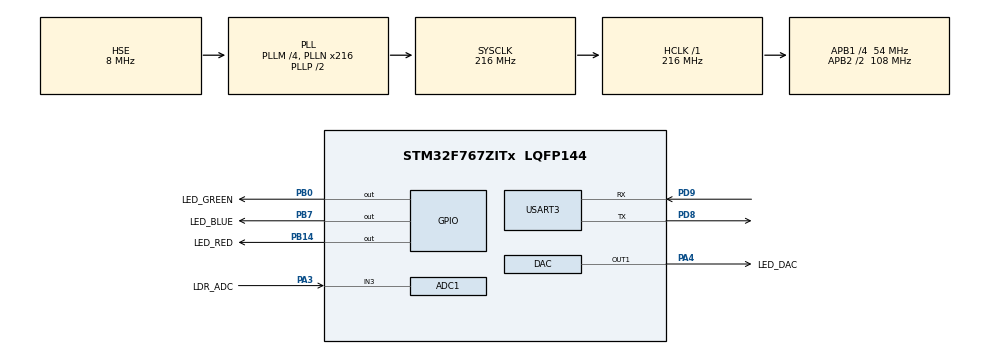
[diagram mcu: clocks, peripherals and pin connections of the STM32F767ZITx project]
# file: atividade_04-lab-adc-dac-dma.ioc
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ADC1.Channel-0\#ChannelRegularConversion=ADC_CHANNEL_3
ADC1.ClockPrescaler=ADC_CLOCK_SYNC_PCLK_DIV8
ADC1.ContinuousConvMode=ENABLE
ADC1.DMAContinuousRequests=ENABLE
ADC1.NbrOfConversionFlag=1
ADC1.Rank-0\#ChannelRegularConversion=1
ADC1.SamplingTime-0\#ChannelRegularConversion=ADC_SAMPLETIME_480CYCLES
ADC1.master=1
Dma.ADC1.0.Direction=DMA_PERIPH_TO_MEMORY
Dma.ADC1.0.FIFOMode=DMA_FIFOMODE_DISABLE
Dma.ADC1.0.Instance=DMA2_Stream0
Dma.ADC1.0.MemDataAlignment=DMA_MDATAALIGN_HALFWORD
Dma.ADC1.0.MemInc=DMA_MINC_ENABLE
Dma.ADC1.0.Mode=DMA_CIRCULAR
Dma.ADC1.0.PeriphDataAlignment=DMA_PDATAALIGN_HALFWORD
Dma.ADC1.0.PeriphInc=DMA_PINC_DISABLE
Dma.ADC1.0.Priority=DMA_PRIORITY_LOW
Dma.Request0=ADC1
Dma.Request1=USART3_RX
Dma.USART3_RX.1.Direction=DMA_PERIPH_TO_MEMORY
Dma.USART3_RX.1.FIFOMode=DMA_FIFOMODE_DISABLE
Dma.USART3_RX.1.Instance=DMA1_Stream1
Dma.USART3_RX.1.MemDataAlignment=DMA_MDATAALIGN_BYTE
Dma.USART3_RX.1.MemInc=DMA_MINC_ENABLE
Dma.USART3_RX.1.Mode=DMA_CIRCULAR
Dma.USART3_RX.1.PeriphDataAlignment=DMA_PDATAALIGN_BYTE
Dma.USART3_RX.1.PeriphInc=DMA_PINC_DISABLE
Dma.USART3_RX.1.Priority=DMA_PRIORITY_MEDIUM
Mcu.Family=STM32F7
Mcu.Name=STM32F767ZITx
Mcu.Package=LQFP144
NVIC.DMA1_Stream1_IRQn=true\:5\:0\:false\:false\:true\:false\:true\:true
NVIC.DMA2_Stream0_IRQn=true\:6\:0\:false\:false\:true\:false\:true\:true
NVIC.PriorityGroup=NVIC_PRIORITYGROUP_4
NVIC.USART3_IRQn=true\:5\:0\:false\:false\:true\:true\:true\:true
PA13.Mode=Serial_Wire
PA13.Signal=SYS_JTMS-SWDIO
PA14.Mode=Serial_Wire
PA14.Signal=SYS_JTCK-SWCLK
PA3.GPIO_Label=LDR_ADC
PA3.Signal=ADCx_IN3
PA4.GPIO_Label=LED_DAC
PA4.Signal=COMP_DAC1_group
PB0.GPIO_Label=LED_GREEN
PB0.Signal=GPIO_Output
PB14.GPIO_Label=LED_RED
PB14.Signal=GPIO_Output
PB7.GPIO_Label=LED_BLUE
PB7.Signal=GPIO_Output
PD8.Mode=Asynchronous
PD8.Signal=USART3_TX
PD9.Mode=Asynchronous
PD9.Signal=USART3_RX
PH0/OSC_IN.Mode=HSE-External-Clock-Source
PH0/OSC_IN.Signal=RCC_OSC_IN
PH1/OSC_OUT.Mode=HSE-External-Clock-Source
PH1/OSC_OUT.Signal=RCC_OSC_OUT
ProjectManager.HeapSize=0x200
ProjectManager.StackSize=0x400
ProjectManager.TargetToolchain=STM32CubeIDE
RCC.AHBFreq_Value=216000000
RCC.APB1CLKDivider=RCC_HCLK_DIV4
RCC.APB1Freq_Value=54000000
RCC.APB1TimFreq_Value=108000000
RCC.APB2CLKDivider=RCC_HCLK_DIV2
RCC.APB2Freq_Value=108000000
RCC.APB2TimFreq_Value=216000000
RCC.CortexFreq_Value=216000000
RCC.HCLKFreq_Value=216000000
RCC.HSE_VALUE=8000000
RCC.HSI_VALUE=16000000
RCC.LSE_VALUE=32768
RCC.PLLM=4
RCC.PLLN=216
RCC.PLLSourceVirtual=RCC_PLLSOURCE_HSE
RCC.SYSCLKFreq_VALUE=216000000
RCC.SYSCLKSource=RCC_SYSCLKSOURCE_PLLCLK
RCC.USBFreq_Value=216000000
RCC.VCOOutputFreq_Value=432000000
SH.ADCx_IN3.0=ADC1_IN3,IN3
SH.COMP_DAC1_group.0=DAC_OUT1,DAC_OUT1
USART3.VirtualMode-Asynchronous=VM_ASYNC
board=custom

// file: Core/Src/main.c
/* USER CODE BEGIN Header */
/**
  ******************************************************************************
  * @file           : main.c
  * @brief          : Main program body
  ******************************************************************************
  * @attention
  *
  * Copyright (c) 2026 STMicroelectronics.
  * All rights reserved.
  *
  * This software is licensed under terms that can be found in the LICENSE file
  * in the root directory of this software component.
  * If no LICENSE file comes with this software, it is provided AS-IS.
  *
  ******************************************************************************
  */
/* USER CODE END Header */
#include "main.h"

/* USER CODE BEGIN Includes */
#include "bsp.h"
#include "app.h"

/* USER CODE END Includes */

ADC_HandleTypeDef hadc1;
DMA_HandleTypeDef hdma_adc1;

DAC_HandleTypeDef hdac;

UART_HandleTypeDef huart3;
DMA_HandleTypeDef hdma_usart3_rx;

void SystemClock_Config(void);
static void MX_GPIO_Init(void);
static void MX_DMA_Init(void);
static void MX_ADC1_Init(void);
static void MX_DAC_Init(void);
static void MX_USART3_UART_Init(void);

int main(void)
{

  /* MCU Configuration--------------------------------------------------------*/

  /* Reset of all peripherals, Initializes the Flash interface and the Systick. */
  HAL_Init();

  /* Configure the system clock */
  SystemClock_Config();

  /* Initialize all configured peripherals */
  MX_GPIO_Init();
  MX_DMA_Init();
  MX_ADC1_Init();
  MX_DAC_Init();
  MX_USART3_UART_Init();
  /* USER CODE BEGIN 2 */
  /* camada de hardware: LEDs, console (DMA), DAC e ADC (DMA) */
  bool bsp_ok = bsp_init(&hadc1, &hdac, &huart3);
  app_init(bsp_ok);           /* digipot + linha de comando */

  /* USER CODE END 2 */

  /* Infinite loop */
  while (1)
  {

    /* USER CODE BEGIN 3 */
    app_loop();               /* superloop bare-metal */
  }
  /* USER CODE END 3 */
}

void SystemClock_Config(void)
{
  RCC_OscInitTypeDef RCC_OscInitStruct = {0};
  RCC_ClkInitTypeDef RCC_ClkInitStruct = {0};

  /** Configure the main internal regulator output voltage
  */
  __HAL_RCC_PWR_CLK_ENABLE();
  __HAL_PWR_VOLTAGESCALING_CONFIG(PWR_REGULATOR_VOLTAGE_SCALE1);

  /** Initializes the RCC Oscillators according to the specified parameters
  * in the RCC_OscInitTypeDef structure.
  */
  RCC_OscInitStruct.OscillatorType = RCC_OSCILLATORTYPE_HSE;
  RCC_OscInitStruct.HSEState = RCC_HSE_BYPASS;
  RCC_OscInitStruct.PLL.PLLState = RCC_PLL_ON;
  RCC_OscInitStruct.PLL.PLLSource = RCC_PLLSOURCE_HSE;
  RCC_OscInitStruct.PLL.PLLM = 4;
  RCC_OscInitStruct.PLL.PLLN = 216;
  RCC_OscInitStruct.PLL.PLLP = RCC_PLLP_DIV2;
  RCC_OscInitStruct.PLL.PLLQ = 2;
  RCC_OscInitStruct.PLL.PLLR = 2;
  if (HAL_RCC_OscConfig(&RCC_OscInitStruct) != HAL_OK)
  {
    Error_Handler();
  }

  /** Activate the Over-Drive mode
  */
  if (HAL_PWREx_EnableOverDrive() != HAL_OK)
  {
    Error_Handler();
  }

  /** Initializes the CPU, AHB and APB buses clocks
  */
  RCC_ClkInitStruct.ClockType = RCC_CLOCKTYPE_HCLK|RCC_CLOCKTYPE_SYSCLK
                              |RCC_CLOCKTYPE_PCLK1|RCC_CLOCKTYPE_PCLK2;
  RCC_ClkInitStruct.SYSCLKSource = RCC_SYSCLKSOURCE_PLLCLK;
  RCC_ClkInitStruct.AHBCLKDivider = RCC_SYSCLK_DIV1;
  RCC_ClkInitStruct.APB1CLKDivider = RCC_HCLK_DIV4;
  RCC_ClkInitStruct.APB2CLKDivider = RCC_HCLK_DIV2;

  if (HAL_RCC_ClockConfig(&RCC_ClkInitStruct, FLASH_LATENCY_7) != HAL_OK)
  {
    Error_Handler();
  }
}

static void MX_ADC1_Init(void)
{

  ADC_ChannelConfTypeDef sConfig = {0};

  /** Configure the global features of the ADC (Clock, Resolution, Data Alignment and number of conversion)
  */
  hadc1.Instance = ADC1;
  hadc1.Init.ClockPrescaler = ADC_CLOCK_SYNC_PCLK_DIV8;
  hadc1.Init.Resolution = ADC_RESOLUTION_12B;
  hadc1.Init.ScanConvMode = ADC_SCAN_DISABLE;
  hadc1.Init.ContinuousConvMode = ENABLE;
  hadc1.Init.DiscontinuousConvMode = DISABLE;
  hadc1.Init.ExternalTrigConvEdge = ADC_EXTERNALTRIGCONVEDGE_NONE;
  hadc1.Init.ExternalTrigConv = ADC_SOFTWARE_START;
  hadc1.Init.DataAlign = ADC_DATAALIGN_RIGHT;
  hadc1.Init.NbrOfConversion = 1;
  hadc1.Init.DMAContinuousRequests = ENABLE;
  hadc1.Init.EOCSelection = ADC_EOC_SINGLE_CONV;
  if (HAL_ADC_Init(&hadc1) != HAL_OK)
  {
    Error_Handler();
  }

  /** Configure for the selected ADC regular channel its corresponding rank in the sequencer and its sample time.
  */
  sConfig.Channel = ADC_CHANNEL_3;
  sConfig.Rank = ADC_REGULAR_RANK_1;
  sConfig.SamplingTime = ADC_SAMPLETIME_480CYCLES;
  if (HAL_ADC_ConfigChannel(&hadc1, &sConfig) != HAL_OK)
  {
    Error_Handler();
  }

}

static void MX_DAC_Init(void)
{

  DAC_ChannelConfTypeDef sConfig = {0};

  /** DAC Initialization
  */
  hdac.Instance = DAC;
  if (HAL_DAC_Init(&hdac) != HAL_OK)
  {
    Error_Handler();
  }

  /** DAC channel OUT1 config
  */
  sConfig.DAC_Trigger = DAC_TRIGGER_NONE;
  sConfig.DAC_OutputBuffer = DAC_OUTPUTBUFFER_ENABLE;
  if (HAL_DAC_ConfigChannel(&hdac, &sConfig, DAC_CHANNEL_1) != HAL_OK)
  {
    Error_Handler();
  }

}

static void MX_USART3_UART_Init(void)
{

  huart3.Instance = USART3;
  huart3.Init.BaudRate = 115200;
  huart3.Init.WordLength = UART_WORDLENGTH_8B;
  huart3.Init.StopBits = UART_STOPBITS_1;
  huart3.Init.Parity = UART_PARITY_NONE;
  huart3.Init.Mode = UART_MODE_TX_RX;
  huart3.Init.HwFlowCtl = UART_HWCONTROL_NONE;
  huart3.Init.OverSampling = UART_OVERSAMPLING_16;
  huart3.Init.OneBitSampling = UART_ONE_BIT_SAMPLE_DISABLE;
  huart3.AdvancedInit.AdvFeatureInit = UART_ADVFEATURE_NO_INIT;
  if (HAL_UART_Init(&huart3) != HAL_OK)
  {
    Error_Handler();
  }

}

static void MX_DMA_Init(void)
{

  /* DMA controller clock enable */
  __HAL_RCC_DMA2_CLK_ENABLE();
  __HAL_RCC_DMA1_CLK_ENABLE();

  /* DMA interrupt init */
  /* DMA1_Stream1_IRQn interrupt configuration */
  HAL_NVIC_SetPriority(DMA1_Stream1_IRQn, 5, 0);
  HAL_NVIC_EnableIRQ(DMA1_Stream1_IRQn);
  /* DMA2_Stream0_IRQn interrupt configuration */
  HAL_NVIC_SetPriority(DMA2_Stream0_IRQn, 6, 0);
  HAL_NVIC_EnableIRQ(DMA2_Stream0_IRQn);

}

static void MX_GPIO_Init(void)
{
  GPIO_InitTypeDef GPIO_InitStruct = {0};

  /* GPIO Ports Clock Enable */
  __HAL_RCC_GPIOH_CLK_ENABLE();
  __HAL_RCC_GPIOA_CLK_ENABLE();
  __HAL_RCC_GPIOB_CLK_ENABLE();
  __HAL_RCC_GPIOD_CLK_ENABLE();

  /*Configure GPIO pin Output Level */
  HAL_GPIO_WritePin(GPIOB, LED_GREEN_Pin|LED_RED_Pin|LED_BLUE_Pin, GPIO_PIN_RESET);

  /*Configure GPIO pins : LED_GREEN_Pin LED_RED_Pin LED_BLUE_Pin */
  GPIO_InitStruct.Pin = LED_GREEN_Pin|LED_RED_Pin|LED_BLUE_Pin;
  GPIO_InitStruct.Mode = GPIO_MODE_OUTPUT_PP;
  GPIO_InitStruct.Pull = GPIO_NOPULL;
  GPIO_InitStruct.Speed = GPIO_SPEED_FREQ_LOW;
  HAL_GPIO_Init(GPIOB, &GPIO_InitStruct);

}

void Error_Handler(void)
{
  __disable_irq();
  while (1)
  {
  }
}
